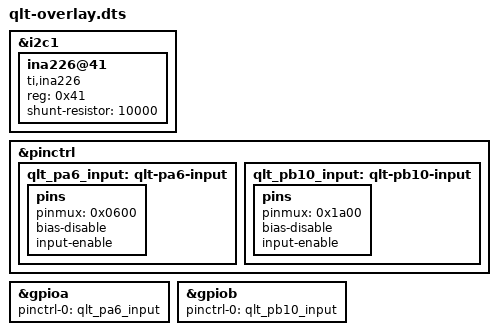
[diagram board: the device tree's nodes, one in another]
// file: qlt-overlay.dts
/dts-v1/;
/plugin/;

/ {
    fragment@0 {
        target = <&i2c1>;
        __overlay__ {
            ina226@41 {
                compatible = "ti,ina226";
                reg = <0x41>;
                shunt-resistor = <10000>;  /* 采样电阻值，单位：微欧 (micro-ohms) */
            };
        };
    };

    fragment@1 {
        target = <&pinctrl>;
        __overlay__ {
            qlt_pa6_input: qlt-pa6-input {
                pins {
                    pinmux = <0x0600>;
                    bias-disable;
                    input-enable;
                };
            };

            qlt_pb10_input: qlt-pb10-input {
                pins {
                    pinmux = <0x1a00>;
                    bias-disable;
                    input-enable;
                };
            };
        };
    };

    fragment@2 {
        target = <&gpioa>;
        __overlay__ {
            pinctrl-names = "default";
            pinctrl-0 = <&qlt_pa6_input>;
        };
    };

    fragment@3 {
        target = <&gpiob>;
        __overlay__ {
            pinctrl-names = "default";
            pinctrl-0 = <&qlt_pb10_input>;
        };
    };
};
